AUTOSAR XML (schema 00050)
package /ComponentTypes
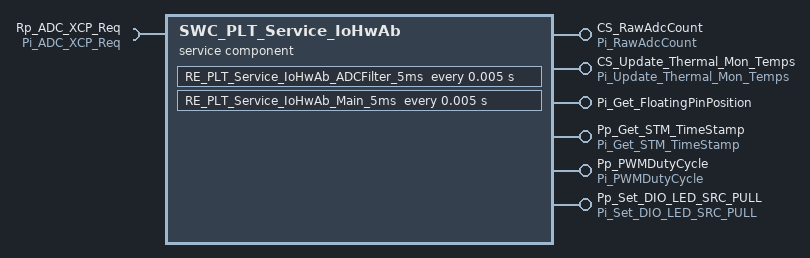
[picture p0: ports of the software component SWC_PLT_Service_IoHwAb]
  service sw component type SWC_PLT_Service_IoHwAb
    6 x provide port:
      CS_RawAdcCount: server-com-spec{operation=Read, queue-length=1}, provided-interface=Pi_RawAdcCount
      CS_Update_Thermal_Mon_Temps: server-com-spec{operation=Read, queue-length=1}, provided-interface=Pi_Update_Thermal_Mon_Temps
      Pi_Get_FloatingPinPosition: server-com-spec{operation=FaultStatus, queue-length=1}, provided-interface=Pi_Get_FloatingPinPosition
      Pp_Get_STM_TimeStamp: server-com-spec{operation=Get_STM_TimeStamp, queue-length=1}, provided-interface=Pi_Get_STM_TimeStamp
      Pp_PWMDutyCycle: server-com-spec{operation=PWMDutyCycle, queue-length=1}, provided-interface=Pi_PWMDutyCycle
      Pp_Set_DIO_LED_SRC_PULL: server-com-spec{operation=Write, queue-length=1}, provided-interface=Pi_Set_DIO_LED_SRC_PULL
    require port Rp_ADC_XCP_Req: nonqueued-receiver-com-spec{data-element=De_ADC_XCP_Req, filter=data-filter-type=ALWAYS, init-value=0}, required-interface=Pi_ADC_XCP_Req
    behavior SWC_PLT_Service_IoHwAb_InternalBehavior
      5 x operation invoked event:
        OIT_CS_RawAdcCount_ADC_Count_Read_CS_RawAdcCount_ADC_Count_Read: start-on-event=CS_RawAdcCount_Read, operation=CS_RawAdcCount.Read
        OIT_CS_Thermal_Mon_Temps_Read_CS_Thermal_Mon_Temps_Read: start-on-event=CS_Update_Thermal_Mon_Temps_Read, operation=CS_Update_Thermal_Mon_Temps.Read
        OIT_Pi_Get_FloatingPinPosition_FaultStatus_Pi_Get_FloatingPinPosition_FaultStatus: start-on-event=Get_FloatingPinPosition_FaultStatus, operation=Pi_Get_FloatingPinPosition.FaultStatus
        OIT_Pp_Get_STM_TimeStamp_Get_STM_TimeStamp_Pp_Get_STM_TimeStamp_Get_STM_TimeStamp: start-on-event=Get_STM_TimeStamp, operation=Pp_Get_STM_TimeStamp.Get_STM_TimeStamp
        OIT_Pp_PWMDutyCycle_PWMDutyCycle_Pp_PWMDutyCycle_PWMDutyCycle: start-on-event=Pp_PWMDutyCycle, operation=Pp_PWMDutyCycle.PWMDutyCycle
      timing event TMT_RE_Service_IoHwAb_ADCFilter_5ms: start-on-event=RE_PLT_Service_IoHwAb_ADCFilter_5ms, period=0.005
      init event SWC_PLT_Service_IoHwAb_InitEvent: start-on-event=RE_PLT_Service_IoHwAb_Init
      timing event TMT_RE_Service_IoHwAb_Main_5ms: start-on-event=RE_PLT_Service_IoHwAb_Main_5ms, period=0.005
      operation invoked event OIT_Pp_Set_DIO_LED_SRC_PULL_Write_Pp_Set_DIO_LED_SRC_PULL_Write: start-on-event=Set_DIO_LED_SRC_PULL, operation=Pp_Set_DIO_LED_SRC_PULL.Write
      port-api-options:
        enable-take-address=false, error-handling=NO-TRANSFORMER-ERROR-HANDLING, indirect-api=false, port=Pp_Get_STM_TimeStamp
        enable-take-address=false, error-handling=NO-TRANSFORMER-ERROR-HANDLING, indirect-api=false, port=Pp_Set_DIO_LED_SRC_PULL
      9 x runnable:
        CS_RawAdcCount_Read
        CS_Update_Thermal_Mon_Temps_Read
        Get_FloatingPinPosition_FaultStatus
        Get_STM_TimeStamp
        Pp_PWMDutyCycle
        RE_PLT_Service_IoHwAb_ADCFilter_5ms
          data-receive-point-by-arguments:
            access REC_Rp_ADC_XCP_Req_De_ADC_XCP_Req: accessed-variable=Rp_ADC_XCP_Req.De_ADC_XCP_Req
        RE_PLT_Service_IoHwAb_Init  # This will initialize all static variables of this SWC
        RE_PLT_Service_IoHwAb_Main_5ms  # This runnable will directly read the ADC values and start the conversions
        Set_DIO_LED_SRC_PULL
  swc implementation SWC_PLT_Service_IoHwAb_Implementation: behavior=SWC_PLT_Service_IoHwAb_InternalBehavior
    code-descriptors:
      code Default: artifact-descriptors=autosar-engineering-object=category=SWSRC
